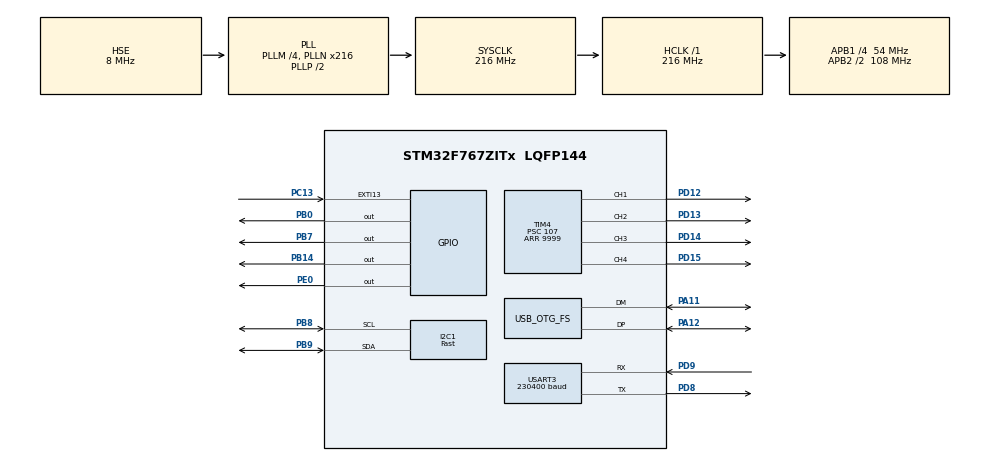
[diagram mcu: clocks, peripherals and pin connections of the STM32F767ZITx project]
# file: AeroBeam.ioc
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I2C1.I2C_Speed_Mode=I2C_Fast
I2C1.Timing=0x6000030D
Mcu.Family=STM32F7
Mcu.Name=STM32F767ZITx
Mcu.Package=LQFP144
NVIC.EXTI15_10_IRQn=true\:0\:0\:false\:false\:true\:true
NVIC.OTG_FS_IRQn=true\:0\:0\:false\:false\:true\:false
NVIC.PriorityGroup=NVIC_PRIORITYGROUP_4
NVIC.TIM6_DAC_IRQn=true\:1\:0\:true\:false\:true\:true
NVIC.USART3_IRQn=true\:1\:0\:true\:false\:true\:true
PA11.Mode=Device_Only
PA11.Signal=USB_OTG_FS_DM
PA12.Mode=Device_Only
PA12.Signal=USB_OTG_FS_DP
PB0.Signal=GPIO_Output
PB14.Signal=GPIO_Output
PB7.Signal=GPIO_Output
PB8.Mode=I2C
PB8.Signal=I2C1_SCL
PB9.Mode=I2C
PB9.Signal=I2C1_SDA
PC13.Signal=GPXTI13
PD12.Signal=S_TIM4_CH1
PD13.Signal=S_TIM4_CH2
PD14.Signal=S_TIM4_CH3
PD15.Signal=S_TIM4_CH4
PD8.Mode=Asynchronous
PD8.Signal=USART3_TX
PD9.Mode=Asynchronous
PD9.Signal=USART3_RX
PE0.Signal=GPIO_Output
PH0/OSC_IN.Mode=HSE-External-Clock-Source
PH0/OSC_IN.Signal=RCC_OSC_IN
PH1/OSC_OUT.Mode=HSE-External-Clock-Source
PH1/OSC_OUT.Signal=RCC_OSC_OUT
ProjectManager.HeapSize=0x2000
ProjectManager.StackSize=0x4000
ProjectManager.TargetToolchain=MDK-ARM V5
RCC.AHBFreq_Value=216000000
RCC.APB1CLKDivider=RCC_HCLK_DIV4
RCC.APB1Freq_Value=54000000
RCC.APB1TimFreq_Value=108000000
RCC.APB2CLKDivider=RCC_HCLK_DIV2
RCC.APB2Freq_Value=108000000
RCC.APB2TimFreq_Value=216000000
RCC.CortexFreq_Value=216000000
RCC.HCLKFreq_Value=216000000
RCC.HSE_VALUE=8000000
RCC.HSI_VALUE=16000000
RCC.LSE_VALUE=32768
RCC.PLLM=4
RCC.PLLN=216
RCC.PLLQ=9
RCC.SYSCLKFreq_VALUE=216000000
RCC.SYSCLKSource=RCC_SYSCLKSOURCE_PLLCLK
RCC.USBFreq_Value=48000000
RCC.VCOOutputFreq_Value=432000000
SH.S_TIM4_CH1.0=TIM4_CH1,PWM Generation1 CH1
SH.S_TIM4_CH2.0=TIM4_CH2,PWM Generation2 CH2
SH.S_TIM4_CH3.0=TIM4_CH3,PWM Generation3 CH3
SH.S_TIM4_CH4.0=TIM4_CH4,PWM Generation4 CH4
TIM4.Channel-PWM\ Generation1\ CH1=TIM_CHANNEL_1
TIM4.Channel-PWM\ Generation2\ CH2=TIM_CHANNEL_2
TIM4.Channel-PWM\ Generation3\ CH3=TIM_CHANNEL_3
TIM4.Channel-PWM\ Generation4\ CH4=TIM_CHANNEL_4
TIM4.Period=9999
TIM4.Prescaler=107
TIM4.Pulse-PWM\ Generation1\ CH1=999
TIM4.Pulse-PWM\ Generation2\ CH2=999
TIM4.Pulse-PWM\ Generation3\ CH3=999
TIM4.Pulse-PWM\ Generation4\ CH4=999
TIM6.Period=999
TIM6.Prescaler=107
USART3.BaudRate=230400
USART3.VirtualMode-Asynchronous=VM_ASYNC
USART3.WordLength=WORDLENGTH_8B
USB_DEVICE.APP_RX_DATA_SIZE-CDC_FS=64
USB_DEVICE.APP_TX_DATA_SIZE-CDC_FS=64
USB_DEVICE.CLASS_NAME_FS=CDC
USB_DEVICE.VirtualMode-CDC_FS=Cdc
USB_DEVICE.VirtualModeFS=Cdc_FS
USB_OTG_FS.VirtualMode=Device_Only
VP_TIM4_VS_ClockSourceINT.Mode=Internal
VP_TIM6_VS_ClockSourceINT.Mode=Enable_Timer
VP_USB_DEVICE_VS_USB_DEVICE_CDC_FS.Mode=CDC_FS
board=AeroBeam

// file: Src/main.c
/**
  ******************************************************************************
  * File Name          : main.c
  * Description        : Main program body
  ******************************************************************************
  * This notice applies to any and all portions of this file
  * that are not between comment pairs USER CODE BEGIN and
  * USER CODE END. Other portions of this file, whether
  * inserted by the user or by software development tools
  * are owned by their respective copyright owners.
  *
  * Copyright (c) 2017 STMicroelectronics International N.V.
  * All rights reserved.
  *
  * Redistribution and use in source and binary forms, with or without
  * modification, are permitted, provided that the following conditions are met:
  *
  * 1. Redistribution of source code must retain the above copyright notice,
  *    this list of conditions and the following disclaimer.
  * 2. Redistributions in binary form must reproduce the above copyright notice,
  *    this list of conditions and the following disclaimer in the documentation
  *    and/or other materials provided with the distribution.
  * 3. Neither the name of STMicroelectronics nor the names of other
  *    contributors to this software may be used to endorse or promote products
  *    derived from this software without specific written permission.
  * 4. This software, including modifications and/or derivative works of this
  *    software, must execute solely and exclusively on microcontroller or
  *    microprocessor devices manufactured by or for STMicroelectronics.
  * 5. Redistribution and use of this software other than as permitted under
  *    this license is void and will automatically terminate your rights under
  *    this license.
  *
  * THIS SOFTWARE IS PROVIDED BY STMICROELECTRONICS AND CONTRIBUTORS "AS IS"
  * AND ANY EXPRESS, IMPLIED OR STATUTORY WARRANTIES, INCLUDING, BUT NOT
  * LIMITED TO, THE IMPLIED WARRANTIES OF MERCHANTABILITY, FITNESS FOR A
  * PARTICULAR PURPOSE AND NON-INFRINGEMENT OF THIRD PARTY INTELLECTUAL PROPERTY
  * RIGHTS ARE DISCLAIMED TO THE FULLEST EXTENT PERMITTED BY LAW. IN NO EVENT
  * SHALL STMICROELECTRONICS OR CONTRIBUTORS BE LIABLE FOR ANY DIRECT, INDIRECT,
  * INCIDENTAL, SPECIAL, EXEMPLARY, OR CONSEQUENTIAL DAMAGES (INCLUDING, BUT NOT
  * LIMITED TO, PROCUREMENT OF SUBSTITUTE GOODS OR SERVICES; LOSS OF USE, DATA,
  * OR PROFITS; OR BUSINESS INTERRUPTION) HOWEVER CAUSED AND ON ANY THEORY OF
  * LIABILITY, WHETHER IN CONTRACT, STRICT LIABILITY, OR TORT (INCLUDING
  * NEGLIGENCE OR OTHERWISE) ARISING IN ANY WAY OUT OF THE USE OF THIS SOFTWARE,
  * EVEN IF ADVISED OF THE POSSIBILITY OF SUCH DAMAGE.
  *
  ******************************************************************************
  */

#include "main.h"
#include "stm32f7xx_hal.h"
#include "i2c.h"
#include "tim.h"
#include "usart.h"
#include "usb_device.h"
#include "gpio.h"

/* USER CODE BEGIN Includes */
#include "aerobeam.h"

/* USER CODE END Includes */

/* USER CODE BEGIN PV */

//uint8_t CDCReceiveNewData=0;

/* Private variables ---------------------------------------------------------*/

/* USER CODE END PV */

void SystemClock_Config(void);

/* USER CODE BEGIN PFP */
/* Private function prototypes -----------------------------------------------*/

/* USER CODE END PFP */

/* USER CODE BEGIN 0 */
void HAL_TIM_PeriodElapsedCallback(TIM_HandleTypeDef *htim)
{
  if(htim->Instance==TIM6) AB_timer_interrupt();
}

void HAL_UART_RxCpltCallback(UART_HandleTypeDef *huart)
{
	if(huart->Instance==USART3) AB_usart3_interrupt();
	HAL_UART_Receive_IT(&huart3,usart3_rx_data,1);
}

/* USER CODE END 0 */

int main(void)
{

  /* MCU Configuration----------------------------------------------------------*/

  /* Reset of all peripherals, Initializes the Flash interface and the Systick. */
  HAL_Init();

  /* Configure the system clock */
  SystemClock_Config();

  /* Initialize all configured peripherals */
  MX_GPIO_Init();
  MX_USB_DEVICE_Init();
  MX_TIM6_Init();
  MX_TIM4_Init();
  MX_I2C1_Init();
  MX_USART3_UART_Init();

  /* USER CODE BEGIN 2 */
	HAL_TIM_PWM_Start(&htim4,TIM_CHANNEL_1);
	HAL_TIM_PWM_Start(&htim4,TIM_CHANNEL_2);
	HAL_TIM_PWM_Start(&htim4,TIM_CHANNEL_3);
	HAL_TIM_PWM_Start(&htim4,TIM_CHANNEL_4);
	AB_setup();
	HAL_UART_Receive_IT(&huart3,usart3_rx_data,1);
	HAL_TIM_Base_Start_IT(&htim6);
  /* USER CODE END 2 */

  /* Infinite loop */
  /* USER CODE BEGIN WHILE */

  while (1)
  {
    AB_loop_while();
  /* USER CODE END WHILE */

  }

}

/** System Clock Configuration
*/
void SystemClock_Config(void)
{

  RCC_OscInitTypeDef RCC_OscInitStruct;
  RCC_ClkInitTypeDef RCC_ClkInitStruct;
  RCC_PeriphCLKInitTypeDef PeriphClkInitStruct;

    /**Configure the main internal regulator output voltage
    */
  __HAL_RCC_PWR_CLK_ENABLE();

  __HAL_PWR_VOLTAGESCALING_CONFIG(PWR_REGULATOR_VOLTAGE_SCALE1);

    /**Initializes the CPU, AHB and APB busses clocks
    */
  RCC_OscInitStruct.OscillatorType = RCC_OSCILLATORTYPE_HSE;
  RCC_OscInitStruct.HSEState = RCC_HSE_BYPASS;
  RCC_OscInitStruct.PLL.PLLState = RCC_PLL_ON;
  RCC_OscInitStruct.PLL.PLLSource = RCC_PLLSOURCE_HSE;
  RCC_OscInitStruct.PLL.PLLM = 4;
  RCC_OscInitStruct.PLL.PLLN = 216;
  RCC_OscInitStruct.PLL.PLLP = RCC_PLLP_DIV2;
  RCC_OscInitStruct.PLL.PLLQ = 9;
  if (HAL_RCC_OscConfig(&RCC_OscInitStruct) != HAL_OK)
  {
    _Error_Handler(__FILE__, __LINE__);
  }

    /**Activate the Over-Drive mode
    */
  if (HAL_PWREx_EnableOverDrive() != HAL_OK)
  {
    _Error_Handler(__FILE__, __LINE__);
  }

    /**Initializes the CPU, AHB and APB busses clocks
    */
  RCC_ClkInitStruct.ClockType = RCC_CLOCKTYPE_HCLK|RCC_CLOCKTYPE_SYSCLK
                              |RCC_CLOCKTYPE_PCLK1|RCC_CLOCKTYPE_PCLK2;
  RCC_ClkInitStruct.SYSCLKSource = RCC_SYSCLKSOURCE_PLLCLK;
  RCC_ClkInitStruct.AHBCLKDivider = RCC_SYSCLK_DIV1;
  RCC_ClkInitStruct.APB1CLKDivider = RCC_HCLK_DIV4;
  RCC_ClkInitStruct.APB2CLKDivider = RCC_HCLK_DIV2;

  if (HAL_RCC_ClockConfig(&RCC_ClkInitStruct, FLASH_LATENCY_7) != HAL_OK)
  {
    _Error_Handler(__FILE__, __LINE__);
  }

  PeriphClkInitStruct.PeriphClockSelection = RCC_PERIPHCLK_USART3|RCC_PERIPHCLK_I2C1
                              |RCC_PERIPHCLK_CLK48;
  PeriphClkInitStruct.Usart3ClockSelection = RCC_USART3CLKSOURCE_PCLK1;
  PeriphClkInitStruct.I2c1ClockSelection = RCC_I2C1CLKSOURCE_PCLK1;
  PeriphClkInitStruct.Clk48ClockSelection = RCC_CLK48SOURCE_PLL;
  if (HAL_RCCEx_PeriphCLKConfig(&PeriphClkInitStruct) != HAL_OK)
  {
    _Error_Handler(__FILE__, __LINE__);
  }

    /**Configure the Systick interrupt time
    */
  HAL_SYSTICK_Config(HAL_RCC_GetHCLKFreq()/1000);

    /**Configure the Systick
    */
  HAL_SYSTICK_CLKSourceConfig(SYSTICK_CLKSOURCE_HCLK);

  /* SysTick_IRQn interrupt configuration */
  HAL_NVIC_SetPriority(SysTick_IRQn, 0, 0);
}

void _Error_Handler(char * file, int line)
{
  while(1)
  {
  }
}

/************************ (C) COPYRIGHT STMicroelectronics *****END OF FILE****/
